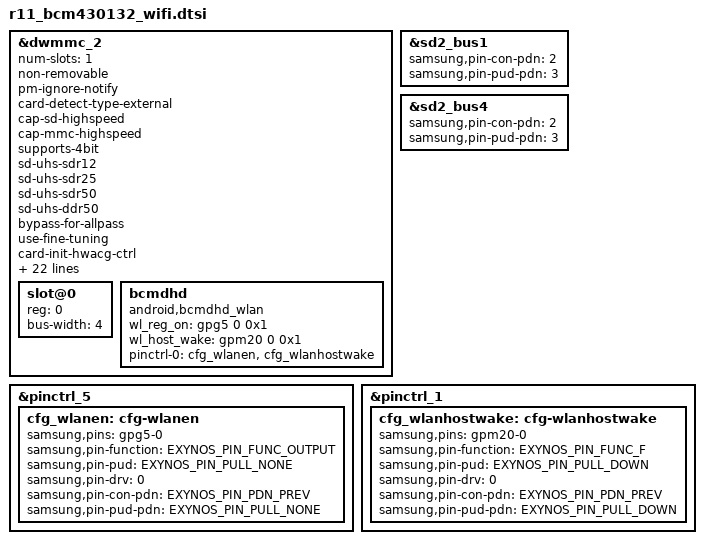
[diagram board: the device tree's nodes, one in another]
/*
* Device Tree config for the BCM430132 chip - WIFI
*/

/***************/
/* SDIO & WIFI */
/***************/

#include <dt-bindings/gpio/gpio.h>
#include <dt-bindings/pinctrl/samsung.h>

/* SDIO (SD) Interface */
&dwmmc_2 {
	#address-cells = <1>;
	#size-cells = <0>;
	status = "okay";
	num-slots = <1>;
	non-removable;
	pm-ignore-notify;
	card-detect-type-external;
	cap-sd-highspeed;
	cap-mmc-highspeed;
	supports-4bit;
	sd-uhs-sdr12;
	sd-uhs-sdr25;
	sd-uhs-sdr50;
	sd-uhs-ddr50;
	bypass-for-allpass;
	use-fine-tuning;
	card-init-hwacg-ctrl;
	only_once_tune;
	skip-init-mmc-scan;
	ignore-phase = <(1 << 7)>;
	fifo-depth = <0x40>;
	desc-size = <4>;
	card-detect-delay = <200>;
	data-timeout = <200>;
	hto-timeout = <80>;
	samsung,dw-mshc-ciu-div = <3>;
	clock-frequency = <50000000>;
	samsung,dw-mshc-sdr-timing = <3 0 2 0>;
	samsung,dw-mshc-ddr-timing = <3 0 2 1>;
	samsung,dw-mshc-sdr50-timing = <3 0 4 2>;

	num-ref-clks = <9>;
	ciu_clkin = <25 50 50 25 50 100 200 50 50>;

	clk-drive-number = <4>;
	pinctrl-names = "init",
		"fast-slew-rate-1x",
		"fast-slew-rate-2x",
		"fast-slew-rate-3x",
		"fast-slew-rate-4x";
	pinctrl-0 = <&sd2_clk &sd2_cmd &sd2_bus1 &sd2_bus4>;
	pinctrl-1 = <&sd2_clk_fast_slew_rate_1x>;
	pinctrl-2 = <&sd2_clk_fast_slew_rate_2x>;
	pinctrl-3 = <&sd2_clk_fast_slew_rate_3x>;
	pinctrl-4 = <&sd2_clk_fast_slew_rate_4x>;

	slot@0 {
		reg = <0>;
		bus-width = <4>;
	};

	/* WIFI */
	bcmdhd {
		compatible = "android,bcmdhd_wlan";
		wl_reg_on = <&gpg5 0 0x1>; /* wlan reg_on pin */
		wl_host_wake = <&gpm20 0 0x1>; /* wlan oob pin */
		pinctrl-names = "default";
		pinctrl-0 = <&cfg_wlanen &cfg_wlanhostwake>;
		status = "okay";
	};
};

/* SDIO - EXTRA PINCTRL CONFIG */
&sd2_bus1 {
	samsung,pin-con-pdn = <2>;	/* Input */
	samsung,pin-pud-pdn = <3>;	/* Pull Up Enable */
};

&sd2_bus4 {
	samsung,pin-con-pdn = <2>;	/* Input */
	samsung,pin-pud-pdn = <3>;	/* Pull Up Enable */
};

/* WIFI - PINCTRL */
&pinctrl_5 {
	cfg_wlanen: cfg-wlanen {
		samsung,pins = "gpg5-0";
		samsung,pin-function = <EXYNOS_PIN_FUNC_OUTPUT>;
		samsung,pin-pud = <EXYNOS_PIN_PULL_NONE>;
		samsung,pin-drv = <0>;		/* 1x */
		samsung,pin-con-pdn = <EXYNOS_PIN_PDN_PREV>;
		samsung,pin-pud-pdn = <EXYNOS_PIN_PULL_NONE>;
	};
};

&pinctrl_1 {
	cfg_wlanhostwake: cfg-wlanhostwake {
		samsung,pins = "gpm20-0";
		samsung,pin-function = <EXYNOS_PIN_FUNC_F>;
		samsung,pin-pud = <EXYNOS_PIN_PULL_DOWN>;
		samsung,pin-drv = <0>;		/* 1x */
		samsung,pin-con-pdn = <EXYNOS_PIN_PDN_PREV>;
		samsung,pin-pud-pdn = <EXYNOS_PIN_PULL_DOWN>;
	};
};
